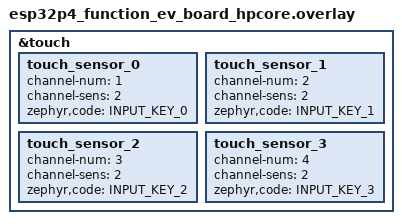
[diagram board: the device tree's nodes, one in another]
/*
 * Copyright (c) 2026 Espressif Systems (Shanghai) Co., Ltd.
 *
 * SPDX-License-Identifier: Apache-2.0
 */

#include <zephyr/dt-bindings/input/input-event-codes.h>

&touch {
	status = "okay";

	touch_sensor_0 {
		channel-num = <1>;
		channel-sens = <2>;
		zephyr,code = <INPUT_KEY_0>;
	};

	touch_sensor_1 {
		channel-num = <2>;
		channel-sens = <2>;
		zephyr,code = <INPUT_KEY_1>;
	};

	touch_sensor_2 {
		channel-num = <3>;
		channel-sens = <2>;
		zephyr,code = <INPUT_KEY_2>;
	};

	touch_sensor_3 {
		channel-num = <4>;
		channel-sens = <2>;
		zephyr,code = <INPUT_KEY_3>;
	};
};
